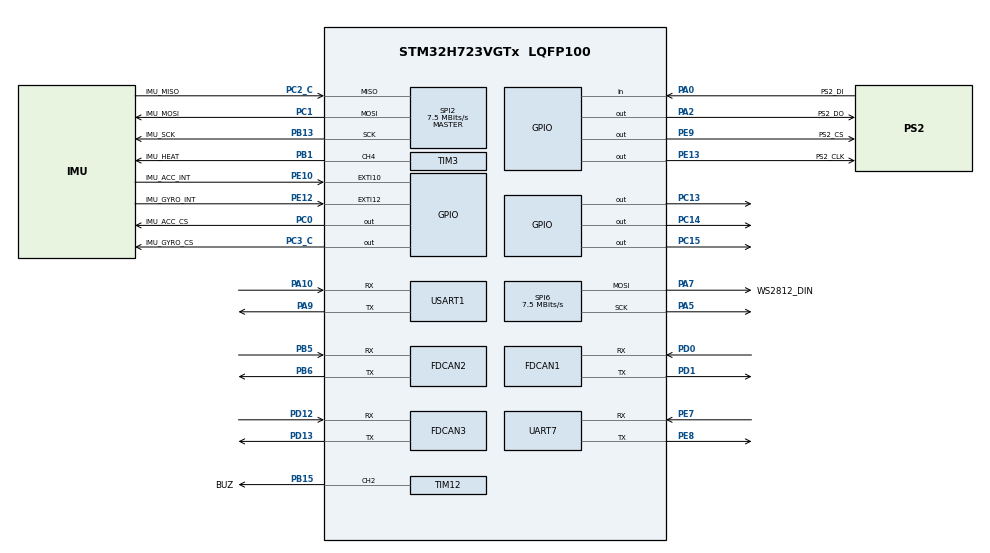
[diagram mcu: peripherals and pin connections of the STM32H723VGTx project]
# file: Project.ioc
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Dma.Request0=SPI2_RX
Dma.Request1=SPI2_TX
Dma.Request2=USART1_RX
Dma.Request3=UART7_RX
Dma.SPI2_RX.0.Direction=DMA_PERIPH_TO_MEMORY
Dma.SPI2_RX.0.EventEnable=DISABLE
Dma.SPI2_RX.0.FIFOMode=DMA_FIFOMODE_DISABLE
Dma.SPI2_RX.0.Instance=DMA1_Stream0
Dma.SPI2_RX.0.MemDataAlignment=DMA_MDATAALIGN_BYTE
Dma.SPI2_RX.0.MemInc=DMA_MINC_ENABLE
Dma.SPI2_RX.0.Mode=DMA_NORMAL
Dma.SPI2_RX.0.PeriphDataAlignment=DMA_PDATAALIGN_BYTE
Dma.SPI2_RX.0.PeriphInc=DMA_PINC_DISABLE
Dma.SPI2_RX.0.Polarity=HAL_DMAMUX_REQ_GEN_RISING
Dma.SPI2_RX.0.Priority=DMA_PRIORITY_VERY_HIGH
Dma.SPI2_RX.0.RequestNumber=1
Dma.SPI2_RX.0.SignalID=NONE
Dma.SPI2_RX.0.SyncEnable=DISABLE
Dma.SPI2_RX.0.SyncPolarity=HAL_DMAMUX_SYNC_NO_EVENT
Dma.SPI2_RX.0.SyncRequestNumber=1
Dma.SPI2_RX.0.SyncSignalID=NONE
Dma.SPI2_TX.1.Direction=DMA_MEMORY_TO_PERIPH
Dma.SPI2_TX.1.EventEnable=DISABLE
Dma.SPI2_TX.1.FIFOMode=DMA_FIFOMODE_DISABLE
Dma.SPI2_TX.1.Instance=DMA1_Stream1
Dma.SPI2_TX.1.MemDataAlignment=DMA_MDATAALIGN_BYTE
Dma.SPI2_TX.1.MemInc=DMA_MINC_ENABLE
Dma.SPI2_TX.1.Mode=DMA_NORMAL
Dma.SPI2_TX.1.PeriphDataAlignment=DMA_PDATAALIGN_BYTE
Dma.SPI2_TX.1.PeriphInc=DMA_PINC_DISABLE
Dma.SPI2_TX.1.Polarity=HAL_DMAMUX_REQ_GEN_RISING
Dma.SPI2_TX.1.Priority=DMA_PRIORITY_HIGH
Dma.SPI2_TX.1.RequestNumber=1
Dma.SPI2_TX.1.SignalID=NONE
Dma.SPI2_TX.1.SyncEnable=DISABLE
Dma.SPI2_TX.1.SyncPolarity=HAL_DMAMUX_SYNC_NO_EVENT
Dma.SPI2_TX.1.SyncRequestNumber=1
Dma.SPI2_TX.1.SyncSignalID=NONE
Dma.UART7_RX.3.Direction=DMA_PERIPH_TO_MEMORY
Dma.UART7_RX.3.EventEnable=DISABLE
Dma.UART7_RX.3.FIFOMode=DMA_FIFOMODE_DISABLE
Dma.UART7_RX.3.Instance=DMA1_Stream4
Dma.UART7_RX.3.MemDataAlignment=DMA_MDATAALIGN_BYTE
Dma.UART7_RX.3.MemInc=DMA_MINC_ENABLE
Dma.UART7_RX.3.Mode=DMA_NORMAL
Dma.UART7_RX.3.PeriphDataAlignment=DMA_PDATAALIGN_BYTE
Dma.UART7_RX.3.PeriphInc=DMA_PINC_DISABLE
Dma.UART7_RX.3.Polarity=HAL_DMAMUX_REQ_GEN_RISING
Dma.UART7_RX.3.Priority=DMA_PRIORITY_VERY_HIGH
Dma.UART7_RX.3.RequestNumber=1
Dma.UART7_RX.3.SignalID=NONE
Dma.UART7_RX.3.SyncEnable=DISABLE
Dma.UART7_RX.3.SyncPolarity=HAL_DMAMUX_SYNC_NO_EVENT
Dma.UART7_RX.3.SyncRequestNumber=1
Dma.UART7_RX.3.SyncSignalID=NONE
Dma.USART1_RX.2.Direction=DMA_PERIPH_TO_MEMORY
Dma.USART1_RX.2.EventEnable=DISABLE
Dma.USART1_RX.2.FIFOMode=DMA_FIFOMODE_DISABLE
Dma.USART1_RX.2.Instance=DMA1_Stream2
Dma.USART1_RX.2.MemDataAlignment=DMA_MDATAALIGN_BYTE
Dma.USART1_RX.2.MemInc=DMA_MINC_ENABLE
Dma.USART1_RX.2.Mode=DMA_NORMAL
Dma.USART1_RX.2.PeriphDataAlignment=DMA_PDATAALIGN_BYTE
Dma.USART1_RX.2.PeriphInc=DMA_PINC_DISABLE
Dma.USART1_RX.2.Polarity=HAL_DMAMUX_REQ_GEN_RISING
Dma.USART1_RX.2.Priority=DMA_PRIORITY_VERY_HIGH
Dma.USART1_RX.2.RequestNumber=1
Dma.USART1_RX.2.SignalID=NONE
Dma.USART1_RX.2.SyncEnable=DISABLE
Dma.USART1_RX.2.SyncPolarity=HAL_DMAMUX_SYNC_NO_EVENT
Dma.USART1_RX.2.SyncRequestNumber=1
Dma.USART1_RX.2.SyncSignalID=NONE
FDCAN1.CalculateBaudRateNominal=1000000
FDCAN1.CalculateTimeBitNominal=1000
FDCAN1.CalculateTimeQuantumNominal=40.0
FDCAN1.DataPrescaler=4
FDCAN1.DataTimeSeg1=19
FDCAN1.DataTimeSeg2=5
FDCAN1.ExtFiltersNbr=5
FDCAN1.NominalPrescaler=4
FDCAN1.NominalTimeSeg1=19
FDCAN1.NominalTimeSeg2=5
FDCAN1.RxFifo0ElmtSize=FDCAN_DATA_BYTES_24
FDCAN1.RxFifo0ElmtsNbr=4
FDCAN1.RxFifo1ElmtSize=FDCAN_DATA_BYTES_24
FDCAN1.StdFiltersNbr=5
FDCAN1.TxElmtSize=FDCAN_DATA_BYTES_24
FDCAN1.TxFifoQueueElmtsNbr=8
FDCAN2.CalculateBaudRateNominal=1000000
FDCAN2.CalculateTimeBitNominal=1000
FDCAN2.CalculateTimeQuantumNominal=50.0
FDCAN2.DataPrescaler=5
FDCAN2.DataTimeSeg1=14
FDCAN2.DataTimeSeg2=5
FDCAN2.ExtFiltersNbr=5
FDCAN2.MessageRAMOffset=854
FDCAN2.NominalPrescaler=5
FDCAN2.NominalTimeSeg1=14
FDCAN2.NominalTimeSeg2=5
FDCAN2.RxFifo1ElmtSize=FDCAN_DATA_BYTES_24
FDCAN2.RxFifo1ElmtsNbr=4
FDCAN2.StdFiltersNbr=5
FDCAN2.TxElmtSize=FDCAN_DATA_BYTES_16
FDCAN2.TxFifoQueueElmtsNbr=4
FDCAN3.CalculateBaudRateNominal=1000000
FDCAN3.CalculateTimeBitNominal=1000
FDCAN3.CalculateTimeQuantumNominal=50.0
FDCAN3.DataPrescaler=5
FDCAN3.DataTimeSeg1=14
FDCAN3.DataTimeSeg2=5
FDCAN3.ExtFiltersNbr=5
FDCAN3.MessageRAMOffset=1709
FDCAN3.NominalPrescaler=5
FDCAN3.NominalTimeSeg1=14
FDCAN3.NominalTimeSeg2=5
FDCAN3.RxFifo0ElmtsNbr=2
FDCAN3.StdFiltersNbr=5
FDCAN3.TxFifoQueueElmtsNbr=3
FREERTOS.MEMORY_ALLOCATION=0
FREERTOS.Tasks01=defaultTask,0,128,StartDefaultTask,Default,NULL,Dynamic,NULL,NULL
FREERTOS.configENABLE_FPU=1
FREERTOS.configTOTAL_HEAP_SIZE=30720
Mcu.Family=STM32H7
Mcu.Name=STM32H723VGTx
Mcu.Package=LQFP100
NVIC.DMA1_Stream0_IRQn=true\:6\:0\:true\:false\:true\:true\:false\:true\:true
NVIC.DMA1_Stream1_IRQn=true\:6\:0\:true\:false\:true\:true\:false\:true\:true
NVIC.DMA1_Stream2_IRQn=true\:5\:0\:false\:false\:true\:true\:false\:true\:true
NVIC.DMA1_Stream4_IRQn=true\:5\:0\:false\:false\:true\:true\:false\:true\:true
NVIC.FDCAN1_IT0_IRQn=true\:6\:0\:true\:false\:true\:true\:true\:true\:true
NVIC.FDCAN2_IT0_IRQn=true\:5\:0\:true\:false\:true\:true\:true\:true\:true
NVIC.FDCAN3_IT0_IRQn=true\:5\:0\:false\:false\:true\:true\:true\:true\:true
NVIC.PriorityGroup=NVIC_PRIORITYGROUP_4
NVIC.SPI2_IRQn=true\:5\:0\:true\:false\:true\:true\:false\:true\:true
NVIC.TIM2_IRQn=true\:15\:0\:false\:false\:true\:false\:false\:true\:true
NVIC.TimeBase=TIM2_IRQn
NVIC.TimeBaseIP=TIM2
NVIC.UART7_IRQn=true\:5\:0\:false\:false\:true\:true\:true\:true\:true
NVIC.USART1_IRQn=true\:5\:0\:false\:false\:true\:true\:true\:true\:true
PA0.GPIO_Label=PS2_DI
PA0.GPIO_PuPd=GPIO_PULLUP
PA0.Signal=GPIO_Input
PA10.Mode=Asynchronous
PA10.Signal=USART1_RX
PA13(JTMS/SWDIO).Mode=Serial_Wire
PA13(JTMS/SWDIO).Signal=DEBUG_JTMS-SWDIO
PA14(JTCK/SWCLK).Mode=Serial_Wire
PA14(JTCK/SWCLK).Signal=DEBUG_JTCK-SWCLK
PA2.GPIO_Label=PS2_DO
PA2.GPIO_PuPd=GPIO_PULLUP
PA2.GPIO_Speed=GPIO_SPEED_FREQ_VERY_HIGH
PA2.PinState=GPIO_PIN_SET
PA2.Signal=GPIO_Output
PA5.Mode=TX_Only_Simplex_Unidirect_Master
PA5.Signal=SPI6_SCK
PA7.GPIO_Label=WS2812_DIN
PA7.Mode=TX_Only_Simplex_Unidirect_Master
PA7.Signal=SPI6_MOSI
PA9.Mode=Asynchronous
PA9.Signal=USART1_TX
PB1.GPIO_Label=IMU_HEAT
PB1.Signal=S_TIM3_CH4
PB13.GPIO_Label=IMU_SCK
PB13.GPIO_Speed=GPIO_SPEED_FREQ_VERY_HIGH
PB13.Mode=Full_Duplex_Master
PB13.Signal=SPI2_SCK
PB15.GPIO_Label=BUZ
PB15.Signal=S_TIM12_CH2
PB5.Mode=FDCAN_Activate
PB5.Signal=FDCAN2_RX
PB6.Mode=FDCAN_Activate
PB6.Signal=FDCAN2_TX
PC0.GPIO_Label=IMU_ACC_CS
PC0.GPIO_Speed=GPIO_SPEED_FREQ_VERY_HIGH
PC0.PinState=GPIO_PIN_SET
PC0.Signal=GPIO_Output
PC1.GPIO_Label=IMU_MOSI
PC1.GPIO_Speed=GPIO_SPEED_FREQ_VERY_HIGH
PC1.Mode=Full_Duplex_Master
PC1.Signal=SPI2_MOSI
PC13.Signal=GPIO_Output
PC14-OSC32_IN.Signal=GPIO_Output
PC15-OSC32_OUT.PinState=GPIO_PIN_RESET
PC15-OSC32_OUT.Signal=GPIO_Output
PC2_C.GPIO_Label=IMU_MISO
PC2_C.GPIO_Speed=GPIO_SPEED_FREQ_VERY_HIGH
PC2_C.Mode=Full_Duplex_Master
PC2_C.Signal=SPI2_MISO
PC3_C.GPIO_Label=IMU_GYRO_CS
PC3_C.GPIO_Speed=GPIO_SPEED_FREQ_VERY_HIGH
PC3_C.PinState=GPIO_PIN_SET
PC3_C.Signal=GPIO_Output
PD0.Mode=FDCAN_Activate
PD0.Signal=FDCAN1_RX
PD1.Mode=FDCAN_Activate
PD1.Signal=FDCAN1_TX
PD12.Mode=FDCAN_Activate
PD12.Signal=FDCAN3_RX
PD13.Mode=FDCAN_Activate
PD13.Signal=FDCAN3_TX
PE10.GPIO_Label=IMU_ACC_INT
PE10.Signal=GPXTI10
PE12.GPIO_Label=IMU_GYRO_INT
PE12.Signal=GPXTI12
PE13.GPIO_Label=PS2_CLK
PE13.GPIO_PuPd=GPIO_PULLUP
PE13.GPIO_Speed=GPIO_SPEED_FREQ_VERY_HIGH
PE13.PinState=GPIO_PIN_SET
PE13.Signal=GPIO_Output
PE7.Mode=Asynchronous
PE7.Signal=UART7_RX
PE8.Mode=Asynchronous
PE8.Signal=UART7_TX
PE9.GPIO_Label=PS2_CS
PE9.GPIO_PuPd=GPIO_PULLUP
PE9.GPIO_Speed=GPIO_SPEED_FREQ_VERY_HIGH
PE9.PinState=GPIO_PIN_SET
PE9.Signal=GPIO_Output
PH0-OSC_IN.Mode=HSE-External-Oscillator
PH0-OSC_IN.Signal=RCC_OSC_IN
PH1-OSC_OUT.Mode=HSE-External-Oscillator
PH1-OSC_OUT.Signal=RCC_OSC_OUT
ProjectManager.HeapSize=0x200
ProjectManager.StackSize=0x800
ProjectManager.TargetToolchain=CMake
RCC.ADCFreq_Value=100000000
RCC.APB1Freq_Value=120000000
RCC.APB2Freq_Value=120000000
RCC.APB3Freq_Value=120000000
RCC.APB4Freq_Value=120000000
RCC.CortexFreq_Value=480000000
RCC.D1PPRE=RCC_APB3_DIV2
RCC.D2PPRE1=RCC_APB1_DIV2
RCC.D2PPRE2=RCC_APB2_DIV2
RCC.D3PPRE=RCC_APB4_DIV2
RCC.DIVM1=2
RCC.DIVM2=24
RCC.DIVN1=40
RCC.DIVN2=200
RCC.DIVP1=1
RCC.FDCANCLockSelection=RCC_FDCANCLKSOURCE_PLL2
RCC.HCLKFreq_Value=240000000
RCC.HPRE=RCC_HCLK_DIV2
RCC.HSE_VALUE=24000000
RCC.PLL2FRACN=0
RCC.PLL3FRACN=0
RCC.PLLFRACN=0
RCC.PLLSourceVirtual=RCC_PLLSOURCE_HSE
RCC.SYSCLKFreq_VALUE=480000000
RCC.SYSCLKSource=RCC_SYSCLKSOURCE_PLLCLK
RCC.USBFreq_Value=240000000
SH.S_TIM12_CH2.0=TIM12_CH2,PWM Generation2 CH2
SH.S_TIM3_CH4.0=TIM3_CH4,PWM Generation4 CH4
SPI2.BaudRatePrescaler=SPI_BAUDRATEPRESCALER_32
SPI2.CLKPhase=SPI_PHASE_2EDGE
SPI2.CLKPolarity=SPI_POLARITY_HIGH
SPI2.CalculateBaudRate=7.5 MBits/s
SPI2.DataSize=SPI_DATASIZE_8BIT
SPI2.Direction=SPI_DIRECTION_2LINES
SPI2.Mode=SPI_MODE_MASTER
SPI2.VirtualType=VM_MASTER
SPI6.BaudRatePrescaler=SPI_BAUDRATEPRESCALER_16
SPI6.CLKPhase=SPI_PHASE_2EDGE
SPI6.CalculateBaudRate=7.5 MBits/s
SPI6.DataSize=SPI_DATASIZE_8BIT
SPI6.Direction=SPI_DIRECTION_2LINES_TXONLY
SPI6.Mode=SPI_MODE_MASTER
SPI6.VirtualType=VM_MASTER
STMicroelectronics.X-CUBE-ALGOBUILD.1.4.0.LibraryCcDSPOoLibraryJjDSPOoLibrary=true
TIM12.Channel-PWM\ Generation2\ CH2=TIM_CHANNEL_2
TIM12.Period=2000-1
TIM12.Prescaler=24-1
TIM12.Pulse-PWM\ Generation2\ CH2=1000
TIM3.AutoReloadPreload=TIM_AUTORELOAD_PRELOAD_ENABLE
TIM3.Channel-PWM\ Generation4\ CH4=TIM_CHANNEL_4
TIM3.Period=10000-1
TIM3.Prescaler=24-1
USART1.OverrunDisableParam=ADVFEATURE_OVERRUN_ENABLE
USART1.VirtualMode-Asynchronous=VM_ASYNC
VP_FREERTOS_VS_CMSIS_V1.Mode=CMSIS_V1
VP_MEMORYMAP_VS_MEMORYMAP.Mode=CurAppReg
VP_STMicroelectronics.X-CUBE-ALGOBUILD_VS_DSPOoLibraryJjLibrary_1.4.0_1.4.0.Mode=DSPOoLibraryJjLibrary
VP_SYS_VS_tim2.Mode=TIM2
board=custom

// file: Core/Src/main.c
/* USER CODE BEGIN Header */
/**
 ******************************************************************************
 * @file           : main.c
 * @brief          : Main program body
 ******************************************************************************
 * @attention
 *
 * Copyright (c) 2025 STMicroelectronics.
 * All rights reserved.
 *
 * This software is licensed under terms that can be found in the LICENSE file
 * in the root directory of this software component.
 * If no LICENSE file comes with this software, it is provided AS-IS.
 *
 ******************************************************************************
 */
/* USER CODE END Header */
#include "main.h"
#include "cmsis_os.h"
#include "dma.h"
#include "fdcan.h"
#include "spi.h"
#include "tim.h"
#include "usart.h"
#include "gpio.h"

/* USER CODE BEGIN Includes */
#include "common_inc.h"
/* USER CODE END Includes */

void SystemClock_Config(void);
void PeriphCommonClock_Config(void);
void MX_FREERTOS_Init(void);

int main(void)
{

  /* MCU Configuration--------------------------------------------------------*/

  /* Reset of all peripherals, Initializes the Flash interface and the Systick. */
  HAL_Init();

  /* Configure the system clock */
  SystemClock_Config();

  /* Configure the peripherals common clocks */
  PeriphCommonClock_Config();

  /* Initialize all configured peripherals */
  MX_GPIO_Init();
  MX_DMA_Init();
  MX_SPI2_Init();
  MX_FDCAN1_Init();
  MX_FDCAN2_Init();
  MX_TIM3_Init();
  MX_FDCAN3_Init();
  MX_SPI6_Init();
  MX_TIM12_Init();
  MX_USART1_UART_Init();
  MX_UART7_Init();

  /* Call init function for freertos objects (in cmsis_os2.c) */
  MX_FREERTOS_Init();

  /* Start scheduler */
  osKernelStart();

  /* We should never get here as control is now taken by the scheduler */

  /* Infinite loop */
    while (1) {

    }
}

void SystemClock_Config(void)
{
  RCC_OscInitTypeDef RCC_OscInitStruct = {0};
  RCC_ClkInitTypeDef RCC_ClkInitStruct = {0};

  /** Supply configuration update enable
  */
  HAL_PWREx_ConfigSupply(PWR_LDO_SUPPLY);

  /** Configure the main internal regulator output voltage
  */
  __HAL_PWR_VOLTAGESCALING_CONFIG(PWR_REGULATOR_VOLTAGE_SCALE0);

  while(!__HAL_PWR_GET_FLAG(PWR_FLAG_VOSRDY)) {}

  /** Initializes the RCC Oscillators according to the specified parameters
  * in the RCC_OscInitTypeDef structure.
  */
  RCC_OscInitStruct.OscillatorType = RCC_OSCILLATORTYPE_HSE;
  RCC_OscInitStruct.HSEState = RCC_HSE_ON;
  RCC_OscInitStruct.PLL.PLLState = RCC_PLL_ON;
  RCC_OscInitStruct.PLL.PLLSource = RCC_PLLSOURCE_HSE;
  RCC_OscInitStruct.PLL.PLLM = 2;
  RCC_OscInitStruct.PLL.PLLN = 40;
  RCC_OscInitStruct.PLL.PLLP = 1;
  RCC_OscInitStruct.PLL.PLLQ = 2;
  RCC_OscInitStruct.PLL.PLLR = 2;
  RCC_OscInitStruct.PLL.PLLRGE = RCC_PLL1VCIRANGE_3;
  RCC_OscInitStruct.PLL.PLLVCOSEL = RCC_PLL1VCOWIDE;
  RCC_OscInitStruct.PLL.PLLFRACN = 0;
  if (HAL_RCC_OscConfig(&RCC_OscInitStruct) != HAL_OK)
  {
    Error_Handler();
  }

  /** Initializes the CPU, AHB and APB buses clocks
  */
  RCC_ClkInitStruct.ClockType = RCC_CLOCKTYPE_HCLK|RCC_CLOCKTYPE_SYSCLK
                              |RCC_CLOCKTYPE_PCLK1|RCC_CLOCKTYPE_PCLK2
                              |RCC_CLOCKTYPE_D3PCLK1|RCC_CLOCKTYPE_D1PCLK1;
  RCC_ClkInitStruct.SYSCLKSource = RCC_SYSCLKSOURCE_PLLCLK;
  RCC_ClkInitStruct.SYSCLKDivider = RCC_SYSCLK_DIV1;
  RCC_ClkInitStruct.AHBCLKDivider = RCC_HCLK_DIV2;
  RCC_ClkInitStruct.APB3CLKDivider = RCC_APB3_DIV2;
  RCC_ClkInitStruct.APB1CLKDivider = RCC_APB1_DIV2;
  RCC_ClkInitStruct.APB2CLKDivider = RCC_APB2_DIV2;
  RCC_ClkInitStruct.APB4CLKDivider = RCC_APB4_DIV2;

  if (HAL_RCC_ClockConfig(&RCC_ClkInitStruct, FLASH_LATENCY_3) != HAL_OK)
  {
    Error_Handler();
  }
}

void PeriphCommonClock_Config(void)
{
  RCC_PeriphCLKInitTypeDef PeriphClkInitStruct = {0};

  /** Initializes the peripherals clock
  */
  PeriphClkInitStruct.PeriphClockSelection = RCC_PERIPHCLK_FDCAN;
  PeriphClkInitStruct.PLL2.PLL2M = 24;
  PeriphClkInitStruct.PLL2.PLL2N = 200;
  PeriphClkInitStruct.PLL2.PLL2P = 2;
  PeriphClkInitStruct.PLL2.PLL2Q = 2;
  PeriphClkInitStruct.PLL2.PLL2R = 2;
  PeriphClkInitStruct.PLL2.PLL2RGE = RCC_PLL2VCIRANGE_0;
  PeriphClkInitStruct.PLL2.PLL2VCOSEL = RCC_PLL2VCOMEDIUM;
  PeriphClkInitStruct.PLL2.PLL2FRACN = 0;
  PeriphClkInitStruct.FdcanClockSelection = RCC_FDCANCLKSOURCE_PLL2;
  if (HAL_RCCEx_PeriphCLKConfig(&PeriphClkInitStruct) != HAL_OK)
  {
    Error_Handler();
  }
}

void HAL_TIM_PeriodElapsedCallback(TIM_HandleTypeDef *htim)
{
  if (htim->Instance == TIM2)
  {
    HAL_IncTick();
  }
}

void Error_Handler(void)
{
    __disable_irq();
    while (1) {
    }
}

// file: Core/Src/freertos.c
/* USER CODE BEGIN Header */
/**
 ******************************************************************************
 * File Name          : freertos.c
 * Description        : Code for freertos applications
 ******************************************************************************
 * @attention
 *
 * Copyright (c) 2025 STMicroelectronics.
 * All rights reserved.
 *
 * This software is licensed under terms that can be found in the LICENSE file
 * in the root directory of this software component.
 * If no LICENSE file comes with this software, it is provided AS-IS.
 *
 ******************************************************************************
 */
/* USER CODE END Header */

#include "FreeRTOS.h"
#include "task.h"
#include "main.h"
#include "cmsis_os.h"

/* USER CODE BEGIN Includes */
#include "common_inc.h"
/* USER CODE END Includes */

osThreadId defaultTaskHandle;

void StartDefaultTask(void const * argument);

void MX_FREERTOS_Init(void); /* (MISRA C 2004 rule 8.1) */

void MX_FREERTOS_Init(void) {

  /* Create the thread(s) */
  /* definition and creation of defaultTask */
  osThreadDef(defaultTask, StartDefaultTask, osPriorityNormal, 0, 128);
  defaultTaskHandle = osThreadCreate(osThread(defaultTask), NULL);

}

void StartDefaultTask(void const * argument)
{
  /* USER CODE BEGIN StartDefaultTask */
    /* Infinite loop */
    taskENTER_CRITICAL();
    APP();
    vTaskDelete(defaultTaskHandle);
    taskEXIT_CRITICAL();
  /* USER CODE END StartDefaultTask */
}
